# RS14100 register map
File version: 1.0
CPU: CM4 r0p1, little endian, MPU, FPU, 4 interrupt priority bits
Registers are 32-bit, read-write, reset 0x0 unless marked. A register's access mark holds for its fields unless they carry their own. Offsets are from the block's base; [hi:lo] are bit positions; {n}, {i} and the like mark numbered series; 'fields as' and 'values as' point back to an identical list.

## POWER_DOMAINS — All the Applications, High Speed Interfaces and Peripherals are segregated into multiple power domains to achieve lower current consumption when they are inactive. At reset, all the domains are powered ON.
Base 0x24048400
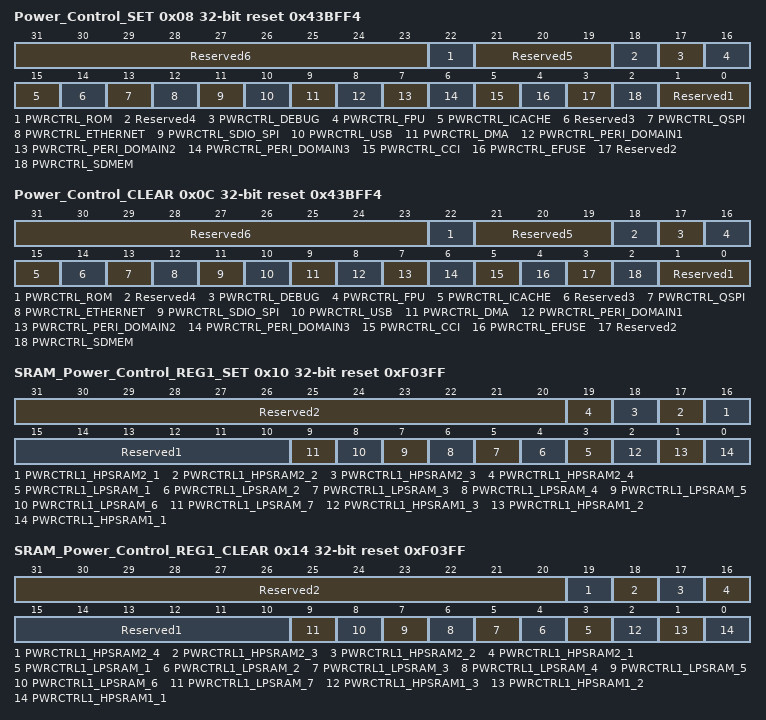
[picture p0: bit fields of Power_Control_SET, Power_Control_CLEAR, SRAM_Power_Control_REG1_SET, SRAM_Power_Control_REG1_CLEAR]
0x08 Power_Control_SET reset 0x43BFF4 — Enables power for APPLICATIONS, HIGH SPEED INTERFACES, HP-PERIPHERALS domains
  [31:23] Reserved6 — It is recommended to write these bits to 0.
  [22] PWRCTRL_ROM — Enable Power to ROM.
    0=Disable (Writing 0 to this has no effect.); 1=Enable (Writing 1 to this enables power to the ROM.)
  [21:19] Reserved5 — It is recommended to write these bits to 0.
  [18] Reserved4 — It is recommended to write these bits to 0.
  [17] PWRCTRL_DEBUG — Enable Power to DEBUG.
    0=Disable (Writing 0 to this has no effect.); 1=Enable (Writing 1 to this enables power to the DEBUG.)
  [16] PWRCTRL_FPU — Enable Power to FPU.
    0=Disable (Writing 0 to this has no effect.); 1=Enable (Writing 1 to this enables power to the FPU.)
  [15] PWRCTRL_ICACHE — Enable Power to ICACHE.
    0=Disable (Writing 0 to this has no effect.); 1=Enable (Writing 1 to this enables power to the ICACHE.)
  [14] Reserved3 — It is recommended to write these bits to 0.
  [13] PWRCTRL_QSPI — Enable Power to QSPI.
    0=Disable (Writing 0 to this has no effect.); 1=Enable (Writing 1 to this enables power to the QSPI.)
  [12] PWRCTRL_ETHERNET — Enable Power to SDIO-SPI Slave.
    0=Disable (Writing 0 to this has no effect.); 1=Enable (Writing 1 to this enables power to the ETHERNET.)
  [11] PWRCTRL_SDIO_SPI — Enable Power to SDIO-SPI Slave.
    0=Disable (Writing 0 to this has no effect.); 1=Enable (Writing 1 to this enables power to the SDIO-SPI Slave.)
  [10] PWRCTRL_USB — Enable Power to USB.
    0=Disable (Writing 0 to this has no effect.); 1=Enable (Writing 1 to this enables power to the USB.)
  [9] PWRCTRL_DMA — Enable Power to DMA.
    0=Disable (Writing 0 to this has no effect.); 1=Enable (Writing 1 to this enables power to the DMA.)
  [8] PWRCTRL_PERI_DOMAIN1 — Enable Power to PERI-DOMAIN1.
    0=Disable (Writing 0 to this has no effect.); 1=Enable (Writing 1 to this enables power to the PERI-DOMAIN1.)
  [7] PWRCTRL_PERI_DOMAIN2 — Enable Power to PERI-DOMAIN2.
    0=Disable (Writing 0 to this has no effect.); 1=Enable (Writing 1 to this enables power to the PERI-DOMAIN2.)
  [6] PWRCTRL_PERI_DOMAIN3 — Enable Power to PERI-DOMAIN3.
    0=Disable (Writing 0 to this has no effect.); 1=Enable (Writing 1 to this enables power to the PERI-DOMAIN3.)
  [5] PWRCTRL_CCI — Enable Power to CCI
    0=Disable (Writing 0 to this has no effect.); 1=Enable (Writing 1 to this enables power to the CCI.)
  [4] PWRCTRL_EFUSE — Enable Power to EFUSE
    0=Disable (Writing 0 to this has no effect.); 1=Enable (Writing 1 to this enables power to the EFUSE.)
  [3] Reserved2 — It is recommended to write these bits to 0.
  [2] PWRCTRL_SDMEM — Enable Power to SDMEM
    0=Disable (Writing 0 to this has no effect.); 1=Enable (Writing 1 to this enables power to the SDMEM.)
  [1:0] Reserved1 — It is recommended to write these bits to 0.
0x0C Power_Control_CLEAR reset 0x43BFF4 — Disables power for APPLICATIONS, HIGH SPEED INTERFACES, HP-PERIPHERALS domains
  [31:23] Reserved6 — It is recommended to write these bits to 0.
  [22] PWRCTRL_ROM — Disable Power to ROM.
    0=Disable (Writing 0 to this has no effect.); 1=Enable (Writing 1 to this disables power to the ROM.)
  [21:19] Reserved5 — It is recommended to write these bits to 0.
  [18] Reserved4 — It is recommended to write these bits to 0.
  [17] PWRCTRL_DEBUG — Disable Power to DEBUG.
    0=Disable (Writing 0 to this has no effect.); 1=Enable (Writing 1 to this disables power to the DEBUG.)
  [16] PWRCTRL_FPU — Disable Power to FPU.
    0=Disable (Writing 0 to this has no effect.); 1=Enable (Writing 1 to this disables power to the FPU.)
  [15] PWRCTRL_ICACHE — Disable Power to ICACHE.
    0=Disable (Writing 0 to this has no effect.); 1=Enable (Writing 1 to this disables power to the ICACHE.)
  [14] Reserved3 — It is recommended to write these bits to 0.
  [13] PWRCTRL_QSPI — Disable Power to QSPI.
    0=Disable (Writing 0 to this has no effect.); 1=Enable (Writing 1 to this disables power to the QSPI.)
  [12] PWRCTRL_ETHERNET — Disable Power to SDIO-SPI Slave.
    0=Disable (Writing 0 to this has no effect.); 1=Enable (Writing 1 to this disables power to the ETHERNET.)
  [11] PWRCTRL_SDIO_SPI — Disable Power to SDIO-SPI Slave.
    0=Disable (Writing 0 to this has no effect.); 1=Enable (Writing 1 to this disables power to the SDIO-SPI Slave.)
  [10] PWRCTRL_USB — Disable Power to USB.
    0=Disable (Writing 0 to this has no effect.); 1=Enable (Writing 1 to this disables power to the USB.)
  [9] PWRCTRL_DMA — Disable Power to DMA.
    0=Disable (Writing 0 to this has no effect.); 1=Enable (Writing 1 to this disables power to the DMA.)
  [8] PWRCTRL_PERI_DOMAIN1 — Disable Power to PERI-DOMAIN1.
    0=Disable (Writing 0 to this has no effect.); 1=Enable (Writing 1 to this disables power to the PERI-DOMAIN1.)
  [7] PWRCTRL_PERI_DOMAIN2 — Disable Power to PERI-DOMAIN2.
    0=Disable (Writing 0 to this has no effect.); 1=Enable (Writing 1 to this disables power to the PERI-DOMAIN2.)
  [6] PWRCTRL_PERI_DOMAIN3 — Disable Power to PERI-DOMAIN3.
    0=Disable (Writing 0 to this has no effect.); 1=Enable (Writing 1 to this disables power to the PERI-DOMAIN3.)
  [5] PWRCTRL_CCI — Disable Power to CCI
    0=Disable (Writing 0 to this has no effect.); 1=Enable (Writing 1 to this disables power to the CCI.)
  [4] PWRCTRL_EFUSE — Disable Power to EFUSE
    0=Disable (Writing 0 to this has no effect.); 1=Enable (Writing 1 to this disables power to the EFUSE.)
  [3] Reserved2 — It is recommended to write these bits to 0.
  [2] PWRCTRL_SDMEM — Disable Power to SDMEM
    0=Disable (Writing 0 to this has no effect.); 1=Enable (Writing 1 to this disables power to the SDMEM.)
  [1:0] Reserved1 — It is recommended to write these bits to 0.
0x10 SRAM_Power_Control_REG1_SET reset 0xF03FF — Enables power for HP-SRAM1, HP-SRAM2 and LP-SRAM domains.
  [31:20] Reserved2 — It is recommended to write these bits to 0.
  [n+15] PWRCTRL1_HPSRAM2_{n} (n=1..4) — It is enables power control1 to all banks in HP-SRAM2-{n}.
    0=Disable (Writing 0 to this has no effect.); 1=Enable (Writing 1 to this enables power to all Banks in HP-SRAM2-{n}.)
  [15:10] Reserved1 — It is recommended to write these bits to 0.
  [n+2] PWRCTRL1_LPSRAM_{n} (n=1..7) — It is enables power control1 to all banks in LP-SRAM-{n}.
    0=Disable (Writing 0 to this has no effect.); 1=Enable (Writing 1 to this enables power to all Banks in LP-SRAM-{n}.)
  [2] PWRCTRL1_HPSRAM1_3 — It is enables power control1 to all banks in HP-SRAM1-3.
    0=Disable (Writing 0 to this has no effect.); 1=Enable (Writing 1 to this enables power to all Banks in HP-SRAM1-3.)
  [1] PWRCTRL1_HPSRAM1_2 — It is enables power control1 to all banks in HP-SRAM1-2.
    0=Disable (Writing 0 to this has no effect.); 1=Enable (Writing 1 to this enables power to all Banks in HP-SRAM1-2.)
  [0] PWRCTRL1_HPSRAM1_1 — It is enables power control1 to all banks in HP-SRAM1-1.
    0=Disable (Writing 0 to this has no effect.); 1=Enable (Writing 1 to this enables power to all Banks in HP-SRAM1-1.)
0x14 SRAM_Power_Control_REG1_CLEAR reset 0xF03FF — Disables power for HP-SRAM, HP-SRAM2 and LP-SRAM domains.
  [31:20] Reserved2 — It is recommended to write these bits to 0.
  [19] PWRCTRL1_HPSRAM2_4 — It is disables power control1 to all banks in HP-SRAM2-4.
    0=Disable (Writing 0 to this has no effect.); 1=Enable (Writing 1 to this disables power to all Banks in HP-SRAM2-4.)
  [18] PWRCTRL1_HPSRAM2_3 — It is disables power control1 to all banks in HP-SRAM2-3.
    0=Disable (Writing 0 to this has no effect.); 1=Enable (Writing 1 to this disables power to all Banks in HP-SRAM2-3.)
  [17] PWRCTRL1_HPSRAM2_2 — It is disables power to all banks in HP-SRAM2-2.
    0=Disable (Writing 0 to this has no effect.); 1=Enable (Writing 1 to this disables power to all Banks in HP-SRAM2-2.)
  [16] PWRCTRL1_HPSRAM2_1 — It is disables power control1 to all banks in HP-SRAM2-1.
    0=Disable (Writing 0 to this has no effect.); 1=Enable (Writing 1 to this disables power to all Banks in HP-SRAM2-1.)
  [15:10] Reserved1 — It is recommended to write these bits to 0.
  [n+2] PWRCTRL1_LPSRAM_{n} (n=1..7) — It is disables power control1 to all banks in LP-SRAM-{n}.
    0=Disable (Writing 0 to this has no effect.); 1=Enable (Writing 1 to this disables power to all Banks in LP-SRAM-{n}.)
  [2] PWRCTRL1_HPSRAM1_3 — It is disables power control1 to all banks in HP-SRAM1-3.
    0=Disable (Writing 0 to this has no effect.); 1=Enable (Writing 1 to this disables power to all Banks in HP-SRAM1-3.)
  [1] PWRCTRL1_HPSRAM1_2 — It is disables power control1 to all banks in HP-SRAM1-2.
    0=Disable (Writing 0 to this has no effect.); 1=Enable (Writing 1 to this disables power to all Banks in HP-SRAM1-2.)
  [0] PWRCTRL1_HPSRAM1_1 — It is disables power control1 to all banks in HP-SRAM1-1.
    0=Disable (Writing 0 to this has no effect.); 1=Enable (Writing 1 to this disables power to all Banks in HP-SRAM1-1.)
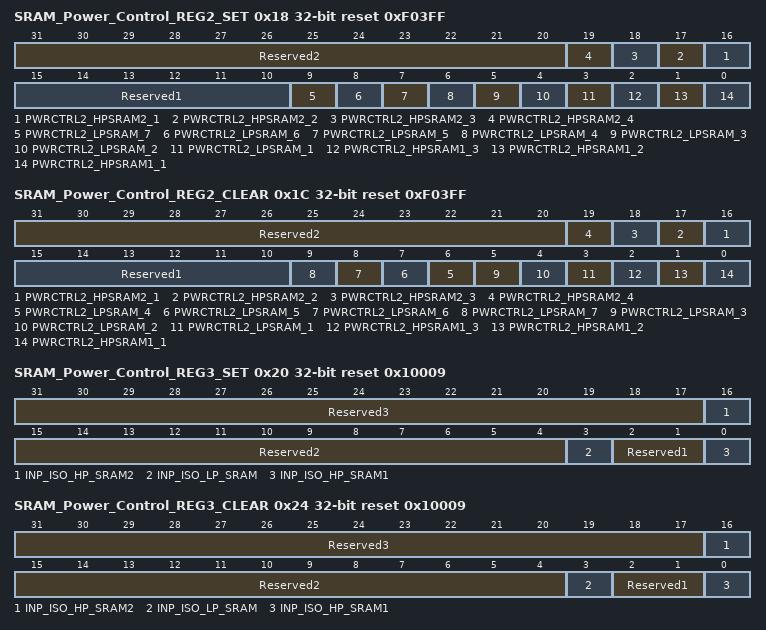
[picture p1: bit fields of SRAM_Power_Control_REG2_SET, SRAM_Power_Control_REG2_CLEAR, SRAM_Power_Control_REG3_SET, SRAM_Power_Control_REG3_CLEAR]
0x18 SRAM_Power_Control_REG2_SET reset 0xF03FF — Enables power for HP-SRAM, HP-SRAM2 and LP-SRAM domains.
  [31:20] Reserved2 — It is recommended to write these bits to 0.
  [n+15] PWRCTRL2_HPSRAM2_{n} (n=1..4) — It is enable power control2 to all banks in HP-SRAM2-{n}.
    values as SRAM_Power_Control_REG1_SET.PWRCTRL1_HPSRAM2_1
  [15:10] Reserved1 — It is recommended to write these bits to 0.
  [9] PWRCTRL2_LPSRAM_7 — It is enable power control2 to all banks in LP-SRAM-7.
    0=Disable (Writing 0 to this has no effect.); 1=Enable (Writing 1 to this enables power to all Banks in LP-SRAM-7.)
  [8] PWRCTRL2_LPSRAM_6 — It is enables power control2 to all banks in LP-SRAM-6.
    0=Disable (Writing 0 to this has no effect.); 1=Enable (Writing 1 to this enables power to all Banks in LP-SRAM-6.)
  [7] PWRCTRL2_LPSRAM_5 — It is enables power control2 to all banks in LP-SRAM-5.
    0=Disable (Writing 0 to this has no effect.); 1=Enable (Writing 1 to this enables power to all Banks in LP-SRAM-5.)
  [6] PWRCTRL2_LPSRAM_4 — It is enable power control2 to all banks in LP-SRAM-4.
    0=Disable (Writing 0 to this has no effect.); 1=Enable (Writing 1 to this enables power to all Banks in LP-SRAM-4.)
  [5] PWRCTRL2_LPSRAM_3 — It is enable power to all banks in LP-SRAM-3.
    0=Disable (Writing 0 to this has no effect.); 1=Enable (Writing 1 to this enables power to all Banks in LP-SRAM-3.)
  [4] PWRCTRL2_LPSRAM_2 — It is enable power control2 to all banks in LP-SRAM-2.
    0=Disable (Writing 0 to this has no effect.); 1=Enable (Writing 1 to this enables power to all Banks in LP-SRAM-2.)
  [3] PWRCTRL2_LPSRAM_1 — It is enable power control2 to all banks in LP-SRAM-1.
    0=Disable (Writing 0 to this has no effect.); 1=Enable (Writing 1 to this enables power to all Banks in LP-SRAM-1.)
  [2] PWRCTRL2_HPSRAM1_3 — It is enable power control2 to all banks in HP-SRAM1-3.
    values as SRAM_Power_Control_REG1_SET.PWRCTRL1_HPSRAM1_3
  [1] PWRCTRL2_HPSRAM1_2 — It is enable power control2 to all banks in HP-SRAM1-2.
    values as SRAM_Power_Control_REG1_SET.PWRCTRL1_HPSRAM1_2
  [0] PWRCTRL2_HPSRAM1_1 — It is enable power control2 to all banks in HP-SRAM1-1.
    values as SRAM_Power_Control_REG1_SET.PWRCTRL1_HPSRAM1_1
0x1C SRAM_Power_Control_REG2_CLEAR reset 0xF03FF — Disables power for HP-SRAM, HP-SRAM2 and LP-SRAM domains.
  [31:20] Reserved2 — It is recommended to write these bits to 0.
  [n+15] PWRCTRL2_HPSRAM2_{n} (n=1..4) — It is disable power control2 to all banks in HP-SRAM2-{n}.
    0=Disable (Writing 0 to this has no effect.); 1=Enable (Writing 1 to this disables power to all Banks in HP-SRAM2-{n}.)
  [15:10] Reserved1 — It is recommended to write these bits to 0.
  [n+2] PWRCTRL2_LPSRAM_{n} (n=4..7) — It is disable power control2 to all banks in LP-SRAM-{n}.
    values as SRAM_Power_Control_REG1_CLEAR.PWRCTRL1_LPSRAM_1
  [5] PWRCTRL2_LPSRAM_3 — It is disable power to all banks in LP-SRAM-3.
    0=Disable (Writing 0 to this has no effect.); 1=Enable (Writing 1 to this disables power to all Banks in LP-SRAM-3.)
  [4] PWRCTRL2_LPSRAM_2 — It is disable power control2 to all banks in LP-SRAM-2.
    0=Disable (Writing 0 to this has no effect.); 1=Enable (Writing 1 to this disables power to all Banks in LP-SRAM-2.)
  [3] PWRCTRL2_LPSRAM_1 — It is disable power control2 to all banks in LP-SRAM-1.
    0=Disable (Writing 0 to this has no effect.); 1=Enable (Writing 1 to this disables power to all Banks in LP-SRAM-1.)
  [2] PWRCTRL2_HPSRAM1_3 — It is disable power control2 to all banks in HP-SRAM1-3.
    values as SRAM_Power_Control_REG1_CLEAR.PWRCTRL1_HPSRAM1_3
  [1] PWRCTRL2_HPSRAM1_2 — It is disable power control2 to all banks in HP-SRAM1-2.
    values as SRAM_Power_Control_REG1_CLEAR.PWRCTRL1_HPSRAM1_2
  [0] PWRCTRL2_HPSRAM1_1 — It is disable power control2 to all banks in HP-SRAM1-1.
    values as SRAM_Power_Control_REG1_CLEAR.PWRCTRL1_HPSRAM1_1
0x20 SRAM_Power_Control_REG3_SET reset 0x10009 — Enables isolation on HP-SRAM, HP-SRAM2 and LP-SRAM input signals.
  [31:17] Reserved3 — It is recommended to write these bits to 0.
  [16] INP_ISO_HP_SRAM2 — It is enables isolation on inputs for HP-SRAM2 Banks.
    0=Disable (Writing 0 to this has no effect.); 1=Enable (Writing 1 to this disables isolation on inputs for HP-SRAM2 Banks.)
  [15:4] Reserved2 — It is recommended to write these bits to 0.
  [3] INP_ISO_LP_SRAM — It is enable isolation on inputs for LP-SRAM Banks.
    0=Disable (Writing 0 to this has no effect.); 1=Enable (Writing 1 to this enables isolation on inputs for LP-SRAM Banks.)
  [2:1] Reserved1 — It is recommended to write these bits to 0.
  [0] INP_ISO_HP_SRAM1 — It is enables isolation on inputs for HP-SRAM1 Banks.
    0=Disable (Writing 0 to this has no effect.); 1=Enable (Writing 1 to this enables isolation on inputs for HP-SRAM1 Banks.)
0x24 SRAM_Power_Control_REG3_CLEAR reset 0x10009 — Disables isolation on HP-SRAM, HP-SRAM2 and LP-SRAM input signals.
  [31:17] Reserved3 — It is recommended to write these bits to 0.
  [16] INP_ISO_HP_SRAM2 — It is disables isolation on inputs for HP-SRAM2 Banks.
    values as SRAM_Power_Control_REG3_SET.INP_ISO_HP_SRAM2
  [15:4] Reserved2 — It is recommended to write these bits to 0.
  [3] INP_ISO_LP_SRAM — It is disable isolation on inputs for LP-SRAM Banks.
    0=Disable (Writing 0 to this has no effect.); 1=Enable (Writing 1 to this disables isolation on inputs for LP-SRAM Banks.)
  [2:1] Reserved1 — It is recommended to write these bits to 0.
  [0] INP_ISO_HP_SRAM1 — It is disables isolation on inputs for HP-SRAM1 Banks.
    0=Disable (Writing 0 to this has no effect.); 1=Enable (Writing 1 to this disables isolation on inputs for HP-SRAM1 Banks.)
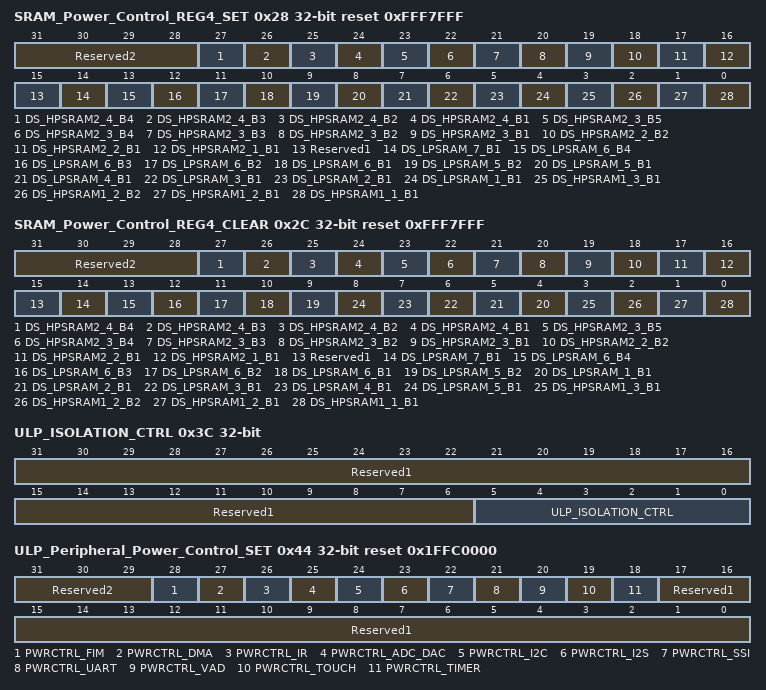
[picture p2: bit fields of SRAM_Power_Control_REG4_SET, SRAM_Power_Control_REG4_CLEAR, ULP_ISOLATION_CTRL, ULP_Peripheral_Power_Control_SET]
0x28 SRAM_Power_Control_REG4_SET reset 0xFFF7FFF — Enables Deep-Sleep for HP-SRAM, HP-SRAM2 and LP-SRAM domains.
  [31:28] Reserved2 — It is recommended to write these bits to 0.
  [27] DS_HPSRAM2_4_B4 — It is enables deep sleep mode to 4th Bank in HP-SRAM2-4.
    0=Disable (Writing 0 to this has no effect.); 1=Enable (Writing 1 to this enables deep sleep mode to 4th Bank in HP-SRAM2-4.)
  [26] DS_HPSRAM2_4_B3 — It is enables deep sleep mode to 3rd Bank in HP-SRAM2-4.
    0=Disable (Writing 0 to this has no effect.); 1=Enable (Writing 1 to this enables deep sleep mode to 3rd Bank in HP-SRAM2-4.)
  [25] DS_HPSRAM2_4_B2 — It is enables deep sleep mode to 2nd Bank in HP-SRAM2-4.
    0=Disable (Writing 0 to this has no effect.); 1=Enable (Writing 1 to this enables deep sleep mode to 2nd Bank in HP-SRAM2-4.)
  [24] DS_HPSRAM2_4_B1 — It is enables deep sleep mode to 1st Bank in HP-SRAM2-4.
    0=Disable (Writing 0 to this has no effect.); 1=Enable (Writing 1 to this enables deep sleep mode to 1st Bank in HP-SRAM2-4.)
  [23] DS_HPSRAM2_3_B5 — It is enables deep sleep mode to 5th Bank in HP-SRAM2-3.
    0=Disable (Writing 0 to this has no effect.); 1=Enable (Writing 1 to this enables deep sleep mode to 5th Bank in HP-SRAM2-3.)
  [22] DS_HPSRAM2_3_B4 — It is enables deep sleep mode to 4th Bank in HP-SRAM2-3.
    0=Disable (Writing 0 to this has no effect.); 1=Enable (Writing 1 to this enables deep sleep mode to 4th Bank in HP-SRAM2-3.)
  [21] DS_HPSRAM2_3_B3 — It is enables deep sleep mode to 3rd Bank in HP-SRAM2-3.
    0=Disable (Writing 0 to this has no effect.); 1=Enable (Writing 1 to this enables deep sleep mode to 3rd Bank in HP-SRAM2-3.)
  [20] DS_HPSRAM2_3_B2 — It is enables deep sleep mode to 2nd Bank in HP-SRAM2-3.
    0=Disable (Writing 0 to this has no effect.); 1=Enable (Writing 1 to this enables deep sleep mode to 2nd Bank in HP-SRAM2-3.)
  [19] DS_HPSRAM2_3_B1 — It is enables deep sleep mode to 1st Bank in HP-SRAM2-3.
    0=Disable (Writing 0 to this has no effect.); 1=Enable (Writing 1 to this enables deep sleep mode to 1st Bank in HP-SRAM2-3.)
  [18] DS_HPSRAM2_2_B2 — It is enables deep sleep mode to 2nd Bank in HP-SRAM2-2.
    0=Disable (Writing 0 to this has no effect.); 1=Enable (Writing 1 to this enables deep sleep mode to 2nd Bank in HP-SRAM2-2.)
  [17] DS_HPSRAM2_2_B1 — It is enables deep sleep mode to 1st Bank in HP-SRAM2-2.
    0=Disable (Writing 0 to this has no effect.); 1=Enable (Writing 1 to this enables deep sleep mode to 1st Bank in HP-SRAM2-2.)
  [16] DS_HPSRAM2_1_B1 — It is enables deep sleep mode to 1st Bank in HP-SRAM2-1.
    0=Disable (Writing 0 to this has no effect.); 1=Enable (Writing 1 to this enables deep sleep mode to 1st Bank in HP-SRAM2-1.)
  [15] Reserved1 — It is recommended to write these bits to 0.
  [14] DS_LPSRAM_7_B1 — It is enables deep sleep mode to 1st Bank in LP-SRAM-7.
    0=Disable (Writing 0 to this has no effect.); 1=Enable (Writing 1 to this enables deep sleep mode to 1st Bank in LP-SRAM-7.)
  [13] DS_LPSRAM_6_B4 — It is enables deep sleep mode to 4th Bank in LP-SRAM-6.
    0=Disable (Writing 0 to this has no effect.); 1=Enable (Writing 1 to this enables deep sleep mode to 4th Bank in LP-SRAM-6.)
  [12] DS_LPSRAM_6_B3 — It is enables deep sleep mode to 3rd Bank in LP-SRAM-6.
    0=Disable (Writing 0 to this has no effect.); 1=Enable (Writing 1 to this enables deep sleep mode to 3rd Bank in LP-SRAM-6.)
  [11] DS_LPSRAM_6_B2 — It is enables deep sleep mode to 2nd Bank in LP-SRAM-6.
    0=Disable (Writing 0 to this has no effect.); 1=Enable (Writing 1 to this enables deep sleep mode to 2nd Bank in LP-SRAM-6.)
  [10] DS_LPSRAM_6_B1 — It is enables deep sleep mode to 1st Bank in LP-SRAM-6.
    0=Disable (Writing 0 to this has no effect.); 1=Enable (Writing 1 to this enables deep sleep mode to 1st Bank in LP-SRAM-6.)
  [9] DS_LPSRAM_5_B2 — It is enables deep sleep mode to 2nd Bank in LP-SRAM-5.
    0=Disable (Writing 0 to this has no effect.); 1=Enable (Writing 1 to this enables deep sleep mode to 2nd Bank in LP-SRAM-5.)
  [8] DS_LPSRAM_5_B1 — It is enables deep sleep mode to 1st Bank in LP-SRAM-5.
    0=Disable (Writing 0 to this has no effect.); 1=Enable (Writing 1 to this enables deep sleep mode to 1st Bank in LP-SRAM-5.)
  [7] DS_LPSRAM_4_B1 — It is enables deep sleep mode to 1st Bank in LP-SRAM-4.
    0=Disable (Writing 0 to this has no effect.); 1=Enable (Writing 1 to this enables deep sleep mode to 1st Bank in LP-SRAM-4.)
  [6] DS_LPSRAM_3_B1 — It is enable deep sleep mode to 1st Bank in LP-SRAM-3.
    0=Disable (Writing 0 to this has no effect.); 1=Enable (Writing 1 to this enables deep sleep mode to 1st Bank in LP-SRAM-3.)
  [5] DS_LPSRAM_2_B1 — It is enable deep sleep mode to 1st Bank in LP-SRAM-2.
    0=Disable (Writing 0 to this has no effect.); 1=Enable (Writing 1 to this enables deep sleep mode to 1st Bank in LP-SRAM-2.)
  [4] DS_LPSRAM_1_B1 — It is enable deep sleep mode to 1st Bank in LP-SRAM-1.
    0=Disable (Writing 0 to this has no effect.); 1=Enable (Writing 1 to this enables deep sleep mode to 1st Bank in LP-SRAM-1.)
  [3] DS_HPSRAM1_3_B1 — It is enable deep sleep mode to 1st Bank in HP-SRAM1-3.
    0=Disable (Writing 0 to this has no effect.); 1=Enable (Writing 1 to this enables deep sleep mode to 1st Bank in HP-SRAM1-3.)
  [2] DS_HPSRAM1_2_B2 — It is enable deep sleep mode to 2nd Bank in HP-SRAM1-2.
    0=Disable (Writing 0 to this has no effect.); 1=Enable (Writing 1 to this enables deep sleep mode to 2nd Bank in HP-SRAM1-2.)
  [1] DS_HPSRAM1_2_B1 — It is enable deep sleep mode to 1st Bank in HP-SRAM1-2.
    0=Disable (Writing 0 to this has no effect.); 1=Enable (Writing 1 to this enables deep sleep mode to 1st Bank in HP-SRAM1-2.)
  [0] DS_HPSRAM1_1_B1 — It is enable deep sleep mode to 1st Bank in HP-SRAM1-1.
    0=Disable (Writing 0 to this has no effect.); 1=Enable (Writing 1 to this enables deep sleep mode to 1st Bank in HP-SRAM1-1.)
0x2C SRAM_Power_Control_REG4_CLEAR reset 0xFFF7FFF — Disables Deep-Sleep for HP-SRAM, HP-SRAM2 and LP-SRAM domains
  [31:28] Reserved2 — It is recommended to write these bits to 0.
  [27] DS_HPSRAM2_4_B4 — It is disable deep sleep mode to 4th Bank in HP-SRAM2-4.
    0=Disable (Writing 0 to this has no effect.); 1=Enable (Writing 1 to this disables deep sleep mode to 4th Bank in HP-SRAM2-4.)
  [26] DS_HPSRAM2_4_B3 — It is disable deep sleep mode to 3rd Bank in HP-SRAM2-4.
    0=Disable (Writing 0 to this has no effect.); 1=Enable (Writing 1 to this disables deep sleep mode to 3rd Bank in HP-SRAM2-4.)
  [25] DS_HPSRAM2_4_B2 — It is disable deep sleep mode to 2nd Bank in HP-SRAM2-4.
    0=Disable (Writing 0 to this has no effect.); 1=Enable (Writing 1 to this disables deep sleep mode to 2nd Bank in HP-SRAM2-4.)
  [24] DS_HPSRAM2_4_B1 — It is disable deep sleep mode to 1st Bank in HP-SRAM2-4.
    0=Disable (Writing 0 to this has no effect.); 1=Enable (Writing 1 to this disables deep sleep mode to 1st Bank in HP-SRAM2-4.)
  [23] DS_HPSRAM2_3_B5 — It is disable deep sleep mode to 5th Bank in HP-SRAM2-3.
    0=Disable (Writing 0 to this has no effect.); 1=Enable (Writing 1 to this disables deep sleep mode to 5th Bank in HP-SRAM2-3.)
  [22] DS_HPSRAM2_3_B4 — It is disable deep sleep mode to 4th Bank in HP-SRAM2-3.
    0=Disable (Writing 0 to this has no effect.); 1=Enable (Writing 1 to this disables deep sleep mode to 4th Bank in HP-SRAM2-3.)
  [21] DS_HPSRAM2_3_B3 — It is disable deep sleep mode to 3rd Bank in HP-SRAM2-3.
    0=Disable (Writing 0 to this has no effect.); 1=Enable (Writing 1 to this disables deep sleep mode to 3rd Bank in HP-SRAM2-3.)
  [20] DS_HPSRAM2_3_B2 — It is disable deep sleep mode to 2nd Bank in HP-SRAM2-3.
    0=Disable (Writing 0 to this has no effect.); 1=Enable (Writing 1 to this disables deep sleep mode to 2nd Bank in HP-SRAM2-3.)
  [19] DS_HPSRAM2_3_B1 — It is disable deep sleep mode to 1st Bank in HP-SRAM2-3.
    0=Disable (Writing 0 to this has no effect.); 1=Enable (Writing 1 to this disables deep sleep mode to 1st Bank in HP-SRAM2-3.)
  [18] DS_HPSRAM2_2_B2 — It is disable deep sleep mode to 2nd Bank in HP-SRAM2-2.
    0=Disable (Writing 0 to this has no effect.); 1=Enable (Writing 1 to this disables deep sleep mode to 2nd Bank in HP-SRAM2-2.)
  [17] DS_HPSRAM2_2_B1 — It is disable deep sleep mode to 1st Bank in HP-SRAM2-2.
    0=Disable (Writing 0 to this has no effect.); 1=Enable (Writing 1 to this disable deep sleep mode to 1st Bank in HP-SRAM2-2.)
  [16] DS_HPSRAM2_1_B1 — It is disable deep sleep mode to 1st Bank in HP-SRAM2-1.
    0=Disable (Writing 0 to this has no effect.); 1=Enable (Writing 1 to this disables deep sleep mode to 1st Bank in HP-SRAM2-1.)
  [15] Reserved1 — It is recommended to write these bits to 0.
  [14] DS_LPSRAM_7_B1 — It is disable deep sleep mode to 1st Bank in LP-SRAM-7.
    0=Disable (Writing 0 to this has no effect.); 1=Enable (Writing 1 to this disables deep sleep mode to 1st Bank in LP-SRAM-7.)
  [13] DS_LPSRAM_6_B4 — It is disable deep sleep mode to 4th Bank in LP-SRAM-6.
    0=Disable (Writing 0 to this has no effect.); 1=Enable (Writing 1 to this disables deep sleep mode to 4th Bank in LP-SRAM-6.)
  [12] DS_LPSRAM_6_B3 — It is disable deep sleep mode to 3rd Bank in LP-SRAM-6.
    0=Disable (Writing 0 to this has no effect.); 1=Enable (Writing 1 to this disables deep sleep mode to 3rd Bank in LP-SRAM-6.)
  [11] DS_LPSRAM_6_B2 — It is disable deep sleep mode to 2nd Bank in LP-SRAM-6.
    0=Disable (Writing 0 to this has no effect.); 1=Enable (Writing 1 to this disables deep sleep mode to 2nd Bank in LP-SRAM-6.)
  [10] DS_LPSRAM_6_B1 — It is disable deep sleep mode to 1st Bank in LP-SRAM-6.
    0=Disable (Writing 0 to this has no effect.); 1=Enable (Writing 1 to this disables deep sleep mode to 1st Bank in LP-SRAM-6.)
  [9] DS_LPSRAM_5_B2 — It is disable deep sleep mode to 2nd Bank in LP-SRAM-5.
    0=Disable (Writing 0 to this has no effect.); 1=Enable (Writing 1 to this disables deep sleep mode to 2nd Bank in LP-SRAM-5.)
  [n+3] DS_LPSRAM_{n}_B1 (n=1..5) — It is disable deep sleep mode to 1st Bank in LP-SRAM-{n}.
    0=Disable (Writing 0 to this has no effect.); 1=Enable (Writing 1 to this disables deep sleep mode to 1st Bank in LP-SRAM-{n}.)
  [3] DS_HPSRAM1_3_B1 — It is disable deep sleep mode to 1st Bank in HP-SRAM1-3.
    0=Disable (Writing 0 to this has no effect.); 1=Enable (Writing 1 to this disables deep sleep mode to 1st Bank in HP-SRAM1-3.)
  [2] DS_HPSRAM1_2_B2 — It is disable deep sleep mode to 2nd Bank in HP-SRAM1-2.
    0=Disable (Writing 0 to this has no effect.); 1=Enable (Writing 1 to this disables deep sleep mode to 2nd Bank in HP-SRAM1-2.)
  [1] DS_HPSRAM1_2_B1 — It is disable deep sleep mode to 1st Bank in HP-SRAM1-2.
    0=Disable (Writing 0 to this has no effect.); 1=Enable (Writing 1 to this disables deep sleep mode to 1st Bank in HP-SRAM1-2.)
  [0] DS_HPSRAM1_1_B1 — It is disable deep sleep mode to 1st Bank in HP-SRAM1-1.
    0=Disable (Writing 0 to this has no effect.); 1=Enable (Writing 1 to this disables deep sleep mode to 1st Bank in HP-SRAM1-1.)
0x3C ULP_ISOLATION_CTRL — Isolation Configuration for Ultra Low-Power Mode of the processor (PS2 State)
  [31:6] Reserved1 — It is recommended to write these bits to 0.
  [5:0] ULP_ISOLATION_CTRL wo — Writing 0xAAAA to this provides immediate trigger to SHIP mode.
    0=Disable (Writing 'h00 to this disables Isolation between Low-Voltage and HIGH VOLTAGE Domains.); 63=Enable (Writing 'h3F to this enables Isolation between Low-Voltage and HIGH VOLTAGE Domains)
0x44 ULP_Peripheral_Power_Control_SET reset 0x1FFC0000 — Enables power for ULP-PERIPHERALS domains
  [31:29] Reserved2 — It is recommended to write these bits to 0.
  [28] PWRCTRL_FIM — It is enable power to FIM
    0=Disable (Writing 0 to this has no effect.); 1=Enable (Writing 1 to this enables power to the FIM.)
  [27] PWRCTRL_DMA — It is enable power to IR
    values as Power_Control_SET.PWRCTRL_DMA
  [26] PWRCTRL_IR — It is enable power to IR
    0=Disable (Writing 0 to this has no effect.); 1=Enable (Writing 1 to this enables power to the IR.)
  [25] PWRCTRL_ADC_DAC — It is enable power to ADC/DAC
    0=Disable (Writing 0 to this has no effect.); 1=Enable (Writing 1 to this enables power to the ADC/DAC.)
  [24] PWRCTRL_I2C — It is enable power to I2C
    0=Disable (Writing 0 to this has no effect.); 1=Enable (Writing 1 to this enables power to the I2C.)
  [23] PWRCTRL_I2S — It is enable power to SPI/SSI
    0=Disable (Writing 0 to this has no effect.); 1=Enable (Writing 1 to this enables power to the I2S.)
  [22] PWRCTRL_SSI — It is enable power to SPI/SSI
    0=Disable (Writing 0 to this has no effect.); 1=Enable (Writing 1 to this enables power to the SPI/SSI.)
  [21] PWRCTRL_UART — It is enable power to UART
    0=Disable (Writing 0 to this has no effect.); 1=Enable (Writing 1 to this enables power to the UART.)
  [20] PWRCTRL_VAD — It is enable power to TOUCH
    0=Disable (Writing 0 to this has no effect.); 1=Enable (Writing 1 to this enables power to the VAD.)
  [19] PWRCTRL_TOUCH — It is enable power to TOUCH
    0=Disable (Writing 0 to this has no effect.); 1=Enable (Writing 1 to this enables power to the TOUCH.)
  [18] PWRCTRL_TIMER — It is enable power to TIMER
    0=Disable (Writing 0 to this has no effect.); 1=Enable (Writing 1 to this enables power to the TIMER.)
  [17:0] Reserved1 — It is recommended to write these bits to 0.
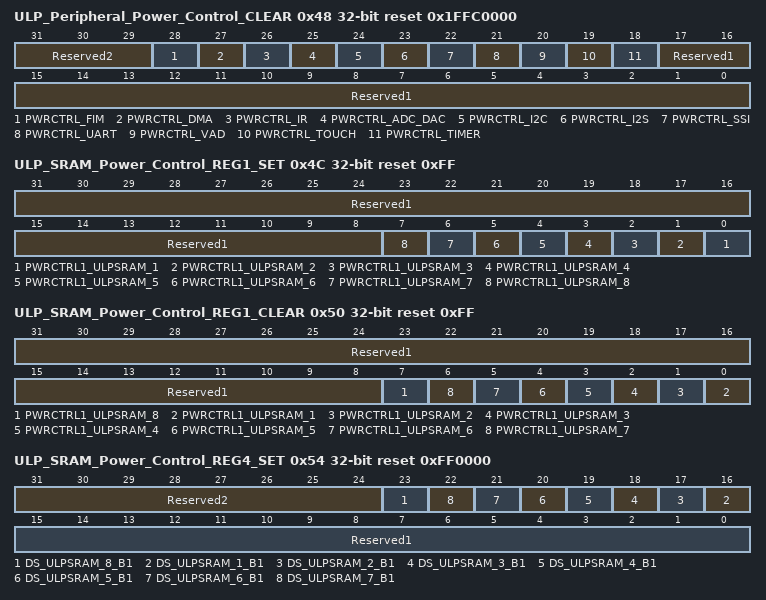
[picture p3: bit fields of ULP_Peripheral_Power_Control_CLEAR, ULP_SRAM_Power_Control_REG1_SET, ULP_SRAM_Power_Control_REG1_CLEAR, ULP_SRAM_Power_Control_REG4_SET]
0x48 ULP_Peripheral_Power_Control_CLEAR reset 0x1FFC0000 — Enables power for ULP-PERIPHERALS domains
  [31:29] Reserved2 — It is recommended to write these bits to 0.
  [28] PWRCTRL_FIM — It is disable power to FIM
    0=Disable (Writing 0 to this has no effect.); 1=Enable (Writing 1 to this disables power to the FIM.)
  [27] PWRCTRL_DMA — It is disable power to IR
    values as Power_Control_CLEAR.PWRCTRL_DMA
  [26] PWRCTRL_IR — It is disable power to IR
    0=Disable (Writing 0 to this has no effect.); 1=Enable (Writing 1 to this disables power to the IR.)
  [25] PWRCTRL_ADC_DAC — It is disable power to ADC/DAC
    0=Disable (Writing 0 to this has no effect.); 1=Enable (Writing 1 to this disables power to the ADC/DAC.)
  [24] PWRCTRL_I2C — It is disable power to I2C
    0=Disable (Writing 0 to this has no effect.); 1=Enable (Writing 1 to this disables power to the I2C.)
  [23] PWRCTRL_I2S — It is disable power to SPI/SSI
    0=Disable (Writing 0 to this has no effect.); 1=Enable (Writing 1 to this disables power to the I2S.)
  [22] PWRCTRL_SSI — It is disable power to SPI/SSI
    0=Disable (Writing 0 to this has no effect.); 1=Enable (Writing 1 to this disables power to the SPI/SSI.)
  [21] PWRCTRL_UART — It is disable power to UART
    0=Disable (Writing 0 to this has no effect.); 1=Enable (Writing 1 to this disables power to the UART.)
  [20] PWRCTRL_VAD — It is disable power to TOUCH
    0=Disable (Writing 0 to this has no effect.); 1=Enable (Writing 1 to this disables power to the VAD.)
  [19] PWRCTRL_TOUCH — It is disable power to TOUCH
    0=Disable (Writing 0 to this has no effect.); 1=Enable (Writing 1 to this disables power to the TOUCH.)
  [18] PWRCTRL_TIMER — It is disable power to TIMER
    0=Disable (Writing 0 to this has no effect.); 1=Enable (Writing 1 to this disables power to the TIMER.)
  [17:0] Reserved1 — It is recommended to write these bits to 0.
0x4C ULP_SRAM_Power_Control_REG1_SET reset 0xFF — Enables power for ULP-PERIPHERALS domains
  [31:8] Reserved1 — It is recommended to write these bits to 0.
  [n-1] PWRCTRL1_ULPSRAM_{n} (n=1..8) — It is enable power to all Banks in ULP-SRAM-{n}.
    0=Disable (Writing 0 to this has no effect.); 1=Enable (Writing 1 to this enables power to all Banks in ULP-SRAM-{n}.)
0x50 ULP_SRAM_Power_Control_REG1_CLEAR reset 0xFF — Disables power for ULP-SRAM domains.
  [31:8] Reserved1 — It is recommended to write these bits to 0.
  [7] PWRCTRL1_ULPSRAM_8 — It is disable power to all Banks in ULP-SRAM-8.
    0=Disable (Writing 0 to this has no effect.); 1=Enable (Writing 1 to this disable power to all Banks in ULP-SRAM-8.)
  [n-1] PWRCTRL1_ULPSRAM_{n} (n=1..7) — It is disable power to all Banks in ULP-SRAM-{n}.
    0=Disable (Writing 0 to this has no effect.); 1=Enable (Writing 1 to this disables power to all Banks in ULP-SRAM-{n}.)
0x54 ULP_SRAM_Power_Control_REG4_SET reset 0xFF0000 — Enables power for ULP-SRAM domains.
  [31:24] Reserved2 — It is recommended to write these bits to 0.
  [23] DS_ULPSRAM_8_B1 — It is enable deep sleep mode to 1st Bank in ULP-SRAM-8
    0=Disable (Writing 0 to this has no effect.); 1=Enable (Writing 1 to this enables deep sleep mode to 1st Bank in ULP-SRAM-8.)
  [n+15] DS_ULPSRAM_{n}_B1 (n=1..7) — It is enable deep sleep mode to 1st Bank in ULP-SRAM-{n}.
    0=Disable (Writing 0 to this has no effect.); 1=Enable (Writing 1 to this enables deep sleep mode to 1st Bank in ULP-SRAM-{n}.)
  [15:0] Reserved1 — It is recommended to write these bits to 0.
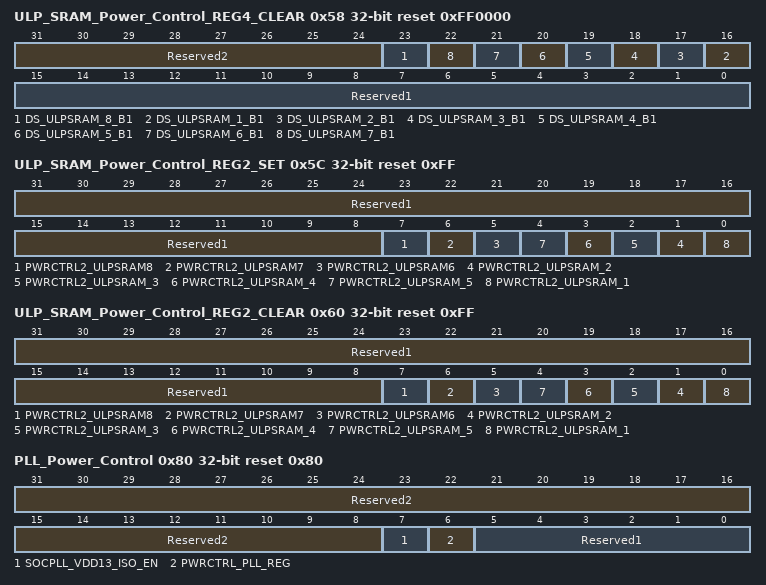
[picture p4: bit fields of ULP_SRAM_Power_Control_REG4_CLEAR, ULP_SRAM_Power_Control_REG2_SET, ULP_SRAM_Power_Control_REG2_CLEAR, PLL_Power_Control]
0x58 ULP_SRAM_Power_Control_REG4_CLEAR reset 0xFF0000 — Disables power for ULP-SRAM domains.
  [31:24] Reserved2 — It is recommended to write these bits to 0.
  [23] DS_ULPSRAM_8_B1 — It is disable deep sleep mode to 1st Bank in ULP-SRAM-8
    0=Disable (Writing 0 to this has no effect.); 1=Enable (Writing 1 to this disables deep sleep mode to 1st Bank in ULP-SRAM-8.)
  [n+15] DS_ULPSRAM_{n}_B1 (n=1..7) — It is disable deep sleep mode to 1st Bank in ULP-SRAM-{n}.
    0=Disable (Writing 0 to this has no effect.); 1=Enable (Writing 1 to this disables deep sleep mode to 1st Bank in ULP-SRAM-{n}.)
  [15:0] Reserved1 — It is recommended to write these bits to 0.
0x5C ULP_SRAM_Power_Control_REG2_SET reset 0xFF — Enables Deep-Sleep for ULP-SRAM domains.
  [31:8] Reserved1 — It is recommended to write these bits to 0.
  [7] PWRCTRL2_ULPSRAM8 — It is enable power control2 to all Banks in ULP-SRAM-8.
    0=Disable (Writing 0 to this has no effect.); 1=Enable (Writing 1 to this enables power to all Banks in ULP-SRAM-8.)
  [6] PWRCTRL2_ULPSRAM7 — It is enable power control2 to all Banks in ULP-SRAM-7.
    0=Disable (Writing 0 to this has no effect.); 1=Enable (Writing 1 to this enables power to all Banks in ULP-SRAM-7.)
  [5] PWRCTRL2_ULPSRAM6 — It is enable power control2 to all Banks in ULP-SRAM-6.
    0=Disable (Writing 0 to this has no effect.); 1=Enable (Writing 1 to this enables power to all Banks in ULP-SRAM-6.)
  [n-1] PWRCTRL2_ULPSRAM_{n} (n=2..5) — It is enable power control2 to all Banks in ULP-SRAM-{n}.
    values as ULP_SRAM_Power_Control_REG1_SET.PWRCTRL1_ULPSRAM_1
  [0] PWRCTRL2_ULPSRAM_1 — It is enable power control2 to all Banks in ULP-SRAM-1.
    0=Disable (Writing 0 to this has no effect.); 1=Enable (Writing 1 to this enables power to all Banks in ULP-SRAM-2.)
0x60 ULP_SRAM_Power_Control_REG2_CLEAR reset 0xFF — Disables Deep-Sleep for ULP-SRAM domains
  [31:8] Reserved1 — It is recommended to write these bits to 0.
  [7] PWRCTRL2_ULPSRAM8 — It is disable power control2 to all Banks in ULP-SRAM-8.
    0=Disable (Writing 0 to this has no effect.); 1=Enable (Writing 1 to this disables power to all Banks in ULP-SRAM-8.)
  [6] PWRCTRL2_ULPSRAM7 — It is disable power control2 to all Banks in ULP-SRAM-7.
    0=Disable (Writing 0 to this has no effect.); 1=Enable (Writing 1 to this disables power to all Banks in ULP-SRAM-7.)
  [5] PWRCTRL2_ULPSRAM6 — It is disable power control2 to all Banks in ULP-SRAM-6.
    0=Disable (Writing 0 to this has no effect.); 1=Enable (Writing 1 to this disables power to all Banks in ULP-SRAM-6.)
  [n-1] PWRCTRL2_ULPSRAM_{n} (n=2..5) — It is disable power control2 to all Banks in ULP-SRAM-{n}.
    values as ULP_SRAM_Power_Control_REG1_CLEAR.PWRCTRL1_ULPSRAM_1
  [0] PWRCTRL2_ULPSRAM_1 — It is disable power control2 to all Banks in ULP-SRAM-1.
    0=Disable (Writing 0 to this has no effect.); 1=Enable (Writing 1 to this disables power to all Banks in ULP-SRAM-2.)
0x80 PLL_Power_Control reset 0x80 — Controls power for HIGH-FREQ-PLL domains.
  [31:8] Reserved2 — It is recommended to write these bits to 0.
  [7] SOCPLL_VDD13_ISO_EN — This is used for isolation of signals from DC-DC 1.35 to the VBATT supply in SoC-PLL to avoid leakage.
    0=Disable (Writing 1 to this enables isolation.); 1=Enable (Writing 0 to this disables isolation.)
  [6] PWRCTRL_PLL_REG — It is enable power to the PLL Programming Registers.
    0=Disable (Writing 0 to this disables power to the PLL Programming Registers.); 1=Enable (Writing 1 to this enables power to the PLL Programming Registers.)
  [5:0] Reserved1 — It is recommended to write these bits to 0.
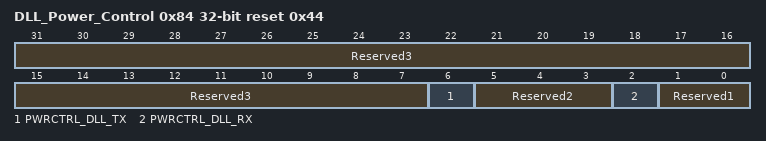
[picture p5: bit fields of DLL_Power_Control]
0x84 DLL_Power_Control reset 0x44 — Controls power for DDR-FLASH-DLL domains
  [31:7] Reserved3 — It is recommended to write these bits to 0.
  [6] PWRCTRL_DLL_TX — It is enable power to the Tx section of DLL
    0=Disable (Writing 0 to this disables power to the Tx Section of DLL); 1=Enable (Writing 1 to this enables power to the Tx Section of DLL)
  [5:3] Reserved2 — It is not recommended to overwrite the content in this bit.
  [2] PWRCTRL_DLL_RX — It is enable power to the Rx section of DLL
    0=Disable (Writing 0 to this disables power to the Rx Section of DLL); 1=Enable (Writing 1 to this enables power to the Rx Section of DLL)
  [1:0] Reserved1 — It is recommended to write these bits to 0.
